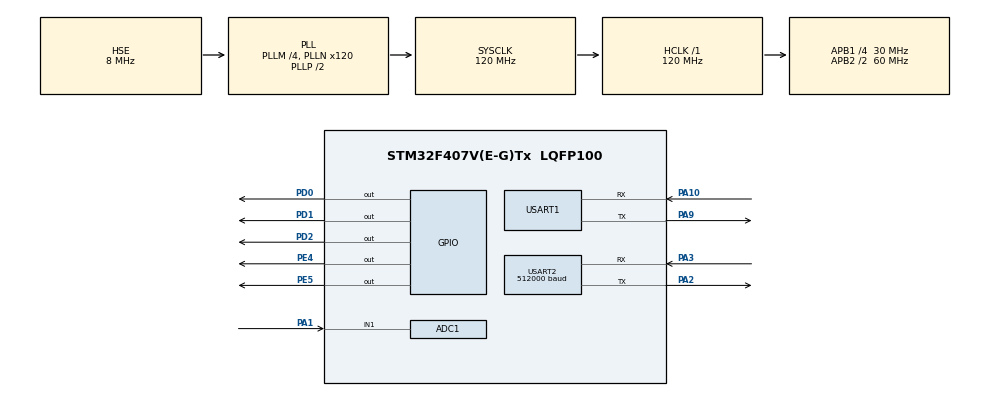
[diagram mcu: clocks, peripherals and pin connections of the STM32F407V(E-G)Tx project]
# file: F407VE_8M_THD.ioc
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ADC1.Channel-0\#ChannelRegularConversion=ADC_CHANNEL_1
ADC1.EnableAnalogWatchDog=true
ADC1.ExternalTrigConv=ADC_EXTERNALTRIGCONV_T2_TRGO
ADC1.HighThreshold=2048
ADC1.ITMode=ENABLE
ADC1.NbrOfConversionFlag=1
ADC1.Rank-0\#ChannelRegularConversion=1
ADC1.Resolution=ADC_RESOLUTION_12B
ADC1.SamplingTime-0\#ChannelRegularConversion=ADC_SAMPLETIME_3CYCLES
ADC1.WatchdogChannel=ADC_CHANNEL_1
ADC1.master=1
Dma.ADC1.0.Direction=DMA_PERIPH_TO_MEMORY
Dma.ADC1.0.FIFOMode=DMA_FIFOMODE_DISABLE
Dma.ADC1.0.Instance=DMA2_Stream0
Dma.ADC1.0.MemDataAlignment=DMA_MDATAALIGN_HALFWORD
Dma.ADC1.0.MemInc=DMA_MINC_ENABLE
Dma.ADC1.0.Mode=DMA_NORMAL
Dma.ADC1.0.PeriphDataAlignment=DMA_PDATAALIGN_HALFWORD
Dma.ADC1.0.PeriphInc=DMA_PINC_DISABLE
Dma.ADC1.0.Priority=DMA_PRIORITY_LOW
Dma.Request0=ADC1
Mcu.Family=STM32F4
Mcu.Name=STM32F407V(E-G)Tx
Mcu.Package=LQFP100
NVIC.ADC_IRQn=true\:0\:0\:false\:false\:true\:true\:true
NVIC.DMA2_Stream0_IRQn=true\:0\:0\:false\:false\:true\:false\:true
NVIC.PriorityGroup=NVIC_PRIORITYGROUP_4
NVIC.USART1_IRQn=true\:0\:0\:false\:false\:true\:true\:true
NVIC.USART2_IRQn=true\:0\:0\:false\:false\:true\:true\:true
PA1.Signal=ADCx_IN1
PA10.Mode=Asynchronous
PA10.Signal=USART1_RX
PA13.Mode=Serial_Wire
PA13.Signal=SYS_JTMS-SWDIO
PA14.Mode=Serial_Wire
PA14.Signal=SYS_JTCK-SWCLK
PA2.Mode=Asynchronous
PA2.Signal=USART2_TX
PA3.Mode=Asynchronous
PA3.Signal=USART2_RX
PA9.Mode=Asynchronous
PA9.Signal=USART1_TX
PC14-OSC32_IN.Mode=LSE-External-Oscillator
PC14-OSC32_IN.Signal=RCC_OSC32_IN
PC15-OSC32_OUT.Mode=LSE-External-Oscillator
PC15-OSC32_OUT.Signal=RCC_OSC32_OUT
PD0.GPIO_ModeDefaultOutputPP=GPIO_MODE_OUTPUT_PP
PD0.GPIO_PuPd=GPIO_NOPULL
PD0.GPIO_Speed=GPIO_SPEED_FREQ_VERY_HIGH
PD0.PinState=GPIO_PIN_RESET
PD0.Signal=GPIO_Output
PD1.GPIO_ModeDefaultOutputPP=GPIO_MODE_OUTPUT_PP
PD1.GPIO_PuPd=GPIO_NOPULL
PD1.GPIO_Speed=GPIO_SPEED_FREQ_VERY_HIGH
PD1.PinState=GPIO_PIN_RESET
PD1.Signal=GPIO_Output
PD2.GPIO_ModeDefaultOutputPP=GPIO_MODE_OUTPUT_PP
PD2.GPIO_PuPd=GPIO_NOPULL
PD2.GPIO_Speed=GPIO_SPEED_FREQ_VERY_HIGH
PD2.PinState=GPIO_PIN_RESET
PD2.Signal=GPIO_Output
PE4.GPIO_ModeDefaultOutputPP=GPIO_MODE_OUTPUT_PP
PE4.GPIO_PuPd=GPIO_PULLUP
PE4.GPIO_Speed=GPIO_SPEED_FREQ_VERY_HIGH
PE4.PinState=GPIO_PIN_SET
PE4.Signal=GPIO_Output
PE5.GPIO_ModeDefaultOutputPP=GPIO_MODE_OUTPUT_PP
PE5.GPIO_PuPd=GPIO_PULLUP
PE5.GPIO_Speed=GPIO_SPEED_FREQ_VERY_HIGH
PE5.PinState=GPIO_PIN_SET
PE5.Signal=GPIO_Output
PH0-OSC_IN.Mode=HSE-External-Oscillator
PH0-OSC_IN.Signal=RCC_OSC_IN
PH1-OSC_OUT.Mode=HSE-External-Oscillator
PH1-OSC_OUT.Signal=RCC_OSC_OUT
ProjectManager.HeapSize=0x250
ProjectManager.StackSize=0x450
ProjectManager.TargetToolchain=MDK-ARM V5.27
RCC.48MHZClocksFreq_Value=60000000
RCC.AHBFreq_Value=120000000
RCC.APB1CLKDivider=RCC_HCLK_DIV4
RCC.APB1Freq_Value=30000000
RCC.APB1TimFreq_Value=60000000
RCC.APB2CLKDivider=RCC_HCLK_DIV2
RCC.APB2Freq_Value=60000000
RCC.APB2TimFreq_Value=120000000
RCC.CortexFreq_Value=120000000
RCC.HCLKFreq_Value=120000000
RCC.HSE_VALUE=8000000
RCC.HSI_VALUE=16000000
RCC.PLLM=4
RCC.PLLN=120
RCC.PLLSourceVirtual=RCC_PLLSOURCE_HSE
RCC.SYSCLKFreq_VALUE=120000000
RCC.SYSCLKSource=RCC_SYSCLKSOURCE_PLLCLK
RCC.VCOOutputFreq_Value=240000000
SH.ADCx_IN1.0=ADC1_IN1,IN1
TIM2.Period=585
TIM2.Prescaler=0
TIM2.TIM_MasterOutputTrigger=TIM_TRGO_UPDATE
USART1.VirtualMode=VM_ASYNC
USART2.BaudRate=512000
USART2.VirtualMode=VM_ASYNC
VP_TIM2_VS_ClockSourceINT.Mode=Internal
board=custom

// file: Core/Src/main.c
/* USER CODE BEGIN Header */
/**
  ******************************************************************************
  * @file           : main.c
  * @brief          : Main program body
  ******************************************************************************
  * @attention
  *
  * <h2><center>&copy; Copyright (c) 2021 STMicroelectronics.
  * All rights reserved.</center></h2>
  *
  * This software component is licensed by ST under BSD 3-Clause license,
  * the "License"; You may not use this file except in compliance with the
  * License. You may obtain a copy of the License at:
  *                        opensource.org/licenses/BSD-3-Clause
  *
  ******************************************************************************
  */
/* USER CODE END Header */
#include "main.h"
#include "adc.h"
#include "dma.h"
#include "tim.h"
#include "usart.h"
#include "gpio.h"

/* USER CODE BEGIN Includes */
#include "hmi.h"
/* USER CODE END Includes */

/* USER CODE BEGIN PD */

uint32_t sampleRate=200000;
/* USER CODE END PD */

/* USER CODE BEGIN PV */
uint16_t val[FFT_LENGTH];
float32_t fftData[FFT_LENGTH];
MyUARTHandle uartHandle1, uartHandle2;
uint8_t uartBuf1[100], uartBuf2[20];
/* USER CODE END PV */

void SystemClock_Config(void);

int main(void)
{

  /* MCU Configuration--------------------------------------------------------*/

  /* Reset of all peripherals, Initializes the Flash interface and the Systick. */
  HAL_Init();

  /* Configure the system clock */
  SystemClock_Config();

  /* Initialize all configured peripherals */
  MX_GPIO_Init();
  MX_DMA_Init();
  MX_USART1_UART_Init();
  MX_ADC1_Init();
  MX_TIM2_Init();
  MX_USART2_UART_Init();
  /* USER CODE BEGIN 2 */
  Delay_Init(120);
  MyUART_Init(&uartHandle1, USART1, uartBuf1, 100);
  MyUART_Init(&uartHandle2, USART2, uartBuf2, 20);
  printf("THD Test\r\n");
  Delay_ms(200);
  /* USER CODE END 2 */

  /* Infinite loop */
  while (1)
  {

    /* USER CODE BEGIN 3 */
    Delay_ms(10);
    HMI_Process();
  }
  /* USER CODE END 3 */
}

void SystemClock_Config(void)
{
  RCC_OscInitTypeDef RCC_OscInitStruct = {0};
  RCC_ClkInitTypeDef RCC_ClkInitStruct = {0};

  /** Configure the main internal regulator output voltage
  */
  __HAL_RCC_PWR_CLK_ENABLE();
  __HAL_PWR_VOLTAGESCALING_CONFIG(PWR_REGULATOR_VOLTAGE_SCALE1);
  /** Initializes the RCC Oscillators according to the specified parameters
  * in the RCC_OscInitTypeDef structure.
  */
  RCC_OscInitStruct.OscillatorType = RCC_OSCILLATORTYPE_HSE;
  RCC_OscInitStruct.HSEState = RCC_HSE_ON;
  RCC_OscInitStruct.PLL.PLLState = RCC_PLL_ON;
  RCC_OscInitStruct.PLL.PLLSource = RCC_PLLSOURCE_HSE;
  RCC_OscInitStruct.PLL.PLLM = 4;
  RCC_OscInitStruct.PLL.PLLN = 120;
  RCC_OscInitStruct.PLL.PLLP = RCC_PLLP_DIV2;
  RCC_OscInitStruct.PLL.PLLQ = 4;
  if (HAL_RCC_OscConfig(&RCC_OscInitStruct) != HAL_OK)
  {
    Error_Handler();
  }
  /** Initializes the CPU, AHB and APB buses clocks
  */
  RCC_ClkInitStruct.ClockType = RCC_CLOCKTYPE_HCLK|RCC_CLOCKTYPE_SYSCLK
                              |RCC_CLOCKTYPE_PCLK1|RCC_CLOCKTYPE_PCLK2;
  RCC_ClkInitStruct.SYSCLKSource = RCC_SYSCLKSOURCE_PLLCLK;
  RCC_ClkInitStruct.AHBCLKDivider = RCC_SYSCLK_DIV1;
  RCC_ClkInitStruct.APB1CLKDivider = RCC_HCLK_DIV4;
  RCC_ClkInitStruct.APB2CLKDivider = RCC_HCLK_DIV2;

  if (HAL_RCC_ClockConfig(&RCC_ClkInitStruct, FLASH_LATENCY_3) != HAL_OK)
  {
    Error_Handler();
  }
}

void Error_Handler(void)
{
  __disable_irq();
  while (1)
  {
  }
}

/************************ (C) COPYRIGHT STMicroelectronics *****END OF FILE****/
